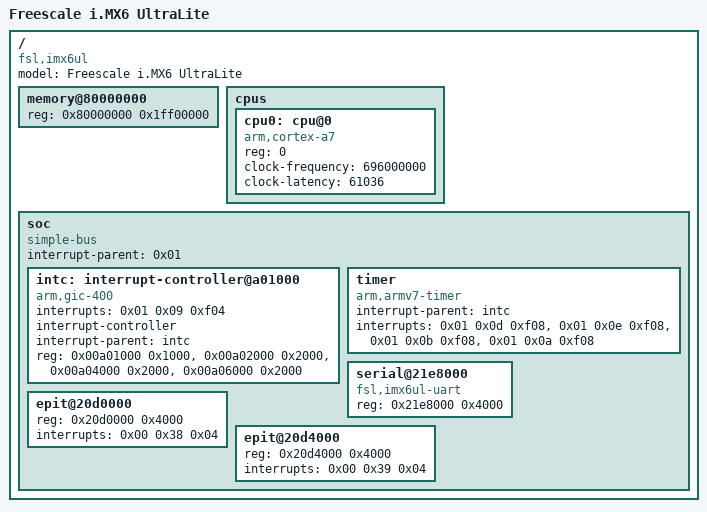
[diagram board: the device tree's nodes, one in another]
/*
 * Copyright Linux Kernel Team
 *
 * SPDX-License-Identifier: GPL-2.0-only
 *
 * This file is derived from an intermediate build stage of the
 * Linux kernel. The licenses of all input files to this process
 * are compatible with GPL-2.0-only.
 */

/dts-v1/;

/ {
	#address-cells = < 0x01 >;
	#size-cells = < 0x01 >;
	model = "Freescale i.MX6 UltraLite";
	compatible = "fsl,imx6ul";

  memory@80000000 {
		device_type = "memory";
		reg = <0x80000000 0x1ff00000>;
	};

  cpus {
		#address-cells = <1>;
		#size-cells = <0>;

		cpu0: cpu@0 {
			compatible = "arm,cortex-a7";
			device_type = "cpu";
			reg = <0>;
			clock-frequency = <696000000>;
			clock-latency = <61036>; /* two CLK32 periods */
		};
  };

  soc {
		#address-cells = < 0x01 >;
		#size-cells = < 0x01 >;
    #interrupt-cells = < 0x03 >;
		compatible = "simple-bus";
		interrupt-parent = < 0x01 >;
		ranges;

    intc: interrupt-controller@a01000 {
			compatible = "arm,gic-400", "arm,cortex-a7-gic";
      #interrupt-cells = < 0x03 >;
			interrupts = <0x01 0x09 0xf04>;
			interrupt-controller;
			interrupt-parent = <&intc>;
			reg = <0x00a01000 0x1000>,
			      <0x00a02000 0x2000>,
			      <0x00a04000 0x2000>,
			      <0x00a06000 0x2000>;
		};

    timer {
      #interrupt-cells = < 0x03 >;
      compatible = "arm,armv7-timer";
      interrupt-parent = <&intc>;
      interrupts = <0x01 0x0d 0xf08>, <0x01 0x0e 0xf08>, <0x01 0x0b 0xf08>, <0x01 0x0a 0xf08>;
    };

    serial@21e8000 {
      compatible = "fsl,imx6ul-uart", "fsl,imx6q-uart";
      reg = < 0x21e8000 0x4000 >;
      status = "okay";
    };

    epit@20d0000 {
      reg = < 0x20d0000 0x4000 >;
      interrupts = < 0x00 0x38 0x04 >;
    };

    epit@20d4000 {
      reg = < 0x20d4000 0x4000 >;
      interrupts = < 0x00 0x39 0x04 >;
    };
  };
};
